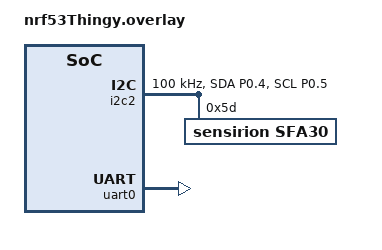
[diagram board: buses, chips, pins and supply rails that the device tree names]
&i2c2 {
	compatible = "nordic,nrf-twim";
	status = "okay";
	clock-frequency = <I2C_BITRATE_STANDARD>;

	pinctrl-0 = <&i2c2_default>;
	pinctrl-1 = <&i2c2_sleep>;
	pinctrl-names = "default", "sleep";


	sfa30@5d {
		status = "okay";
		compatible = "sensirion,sfa30";
		reg = <0x5d>;
		model = "sfa30";

	};



};


&uart0 {
	status = "okay";
	hw-flow-control;
};




&pinctrl {
	i2c2_default: i2c2_default {
		group1 {
			psels = <NRF_PSEL(TWIM_SDA, 0, 4)>,
					<NRF_PSEL(TWIM_SCL, 0, 5)>;
		};
	};

	i2c2_sleep: i2c2_sleep {
		group1 {
			psels = <NRF_PSEL(TWIM_SDA, 0, 4)>,
					<NRF_PSEL(TWIM_SCL, 0, 5)>;
			low-power-enable;
		};
	};
};
